# STM32H7B0x register map
File version: 1.0
CPU: CM7 r0p1, little endian, MPU, FPU, 4 interrupt priority bits
Registers are 32-bit, read-write, reset 0x0 unless marked. A register's access mark holds for its fields unless they carry their own. Offsets are from the block's base; [hi:lo] are bit positions; {n}, {i} and the like mark numbered series.

## NVIC — Nested Vectored Interrupt Controller
Base 0xE000E100
{0x0+4i} ISER{i} (i=0..2) — Interrupt Set-Enable Register
  [31:0] SETENA
{0x80+4i} ICER{i} (i=0..2) — Interrupt Clear-Enable Register
  [31:0] CLRENA
{0x100+4i} ISPR{i} (i=0..2) — Interrupt Set-Pending Register
  [31:0] SETPEND
{0x180+4i} ICPR{i} (i=0..2) — Interrupt Clear-Pending Register
  [31:0] CLRPEND
{0x200+4i} IABR{i} ro (i=0..2) — Interrupt Active Bit Register
  [31:0] ACTIVE
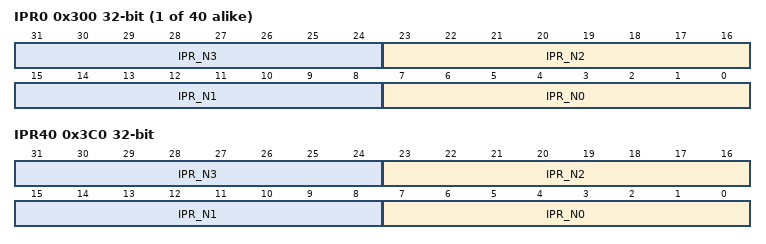
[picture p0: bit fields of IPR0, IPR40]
{0x300+4i} IPR{i} (i=0..39) — Interrupt Priority Register
  [8n+7:8n] IPR_N{n} (n=0..3)
0x3A0 ISER3 — Interrupt Set-Enable Register
  [31:0] SETENA
0x3A4 ISER4 — Interrupt Set-Enable Register
  [31:0] SETENA
0x3A8 ICER3 — Interrupt Clear-Enable Register
  [31:0] CLRENA
0x3AC ICER4 — Interrupt Clear-Enable Register
  [31:0] CLRENA
0x3B0 ISPR3 — Interrupt Set-Pending Register
  [31:0] SETPEND
0x3B4 ISPR4 — Interrupt Set-Pending Register
  [31:0] SETPEND
0x3B8 IABR3 ro — Interrupt Active Bit Register
  [31:0] ACTIVE
0x3BC IABR4 ro — Interrupt Active Bit Register
  [31:0] ACTIVE
0x3C0 IPR40 — Interrupt Priority Register
  [8n+7:8n] IPR_N{n} (n=0..3)

## DBGMCU — Microcontroller Debug Unit
Base 0x5C001000
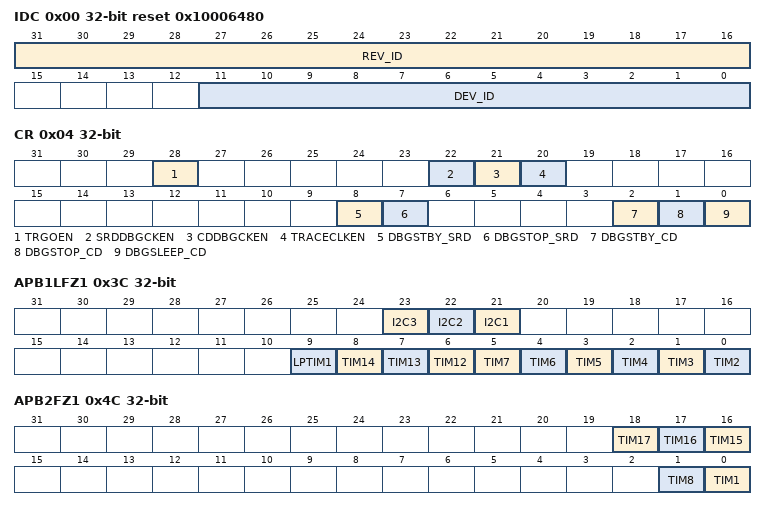
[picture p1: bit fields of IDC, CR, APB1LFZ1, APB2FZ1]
0x00 IDC ro reset 0x10006480 — DBGMCU Identity Code Register
  [31:16] REV_ID — Revision
  [11:0] DEV_ID — Device ID
0x04 CR — DBGMCU Configuration Register
  [28] TRGOEN — External trigger output enable
  [22] SRDDBGCKEN — SmartRun domain debug clock enable
  [21] CDDBGCKEN — CPU domain debug clock enable
  [20] TRACECLKEN — Trace port clock enable
  [8] DBGSTBY_SRD — debug in SmartRun domain Standby mode
  [7] DBGSTOP_SRD — debug in SmartRun domain Stop mode
  [2] DBGSTBY_CD — Allow D1 domain debug in Standby mode
  [1] DBGSTOP_CD — Allow D1 domain debug in Stop mode
  [0] DBGSLEEP_CD — Allow D1 domain debug in Sleep mode
0x34 APB3FZ1 — DBGMCU APB3 peripheral freeze register
  [6] WWDG — WWDG stop in debug
0x3C APB1LFZ1 — DBGMCU APB1L peripheral freeze register
  [23] I2C3 — I2C3 SMBUS timeout stop in debug
  [22] I2C2 — I2C2 SMBUS timeout stop in debug
  [21] I2C1 — I2C1 SMBUS timeout stop in debug
  [9] LPTIM1 — LPTIM1 stop in debug
  [8] TIM14 — TIM14 stop in debug
  [7] TIM13 — TIM13 stop in debug
  [6] TIM12 — TIM12 stop in debug
  [n-2] TIM{n} (n=2..7) — TIM{n} stop in debug
0x4C APB2FZ1 — DBGMCU APB2 peripheral freeze register
  [18] TIM17 — TIM17 stop in debug
  [17] TIM16 — TIM16 stop in debug
  [16] TIM15 — TIM15 stop in debug
  [1] TIM8 — TIM8 stop in debug
  [0] TIM1 — TIM1 stop in debug
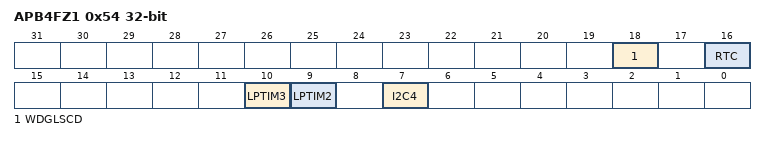
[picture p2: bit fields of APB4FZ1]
0x54 APB4FZ1 — DBGMCU APB4 peripheral freeze register
  [18] WDGLSCD — LS watchdog for CPU domain stop in debug
  [16] RTC — RTC stop in debug
  [10] LPTIM3 — LPTIM3 stop in debug
  [9] LPTIM2 — LPTIM2 stop in debug
  [7] I2C4 — I2C4 SMBUS timeout stop in debug

## SYSCFG — System configuration controller
Base 0x58000400
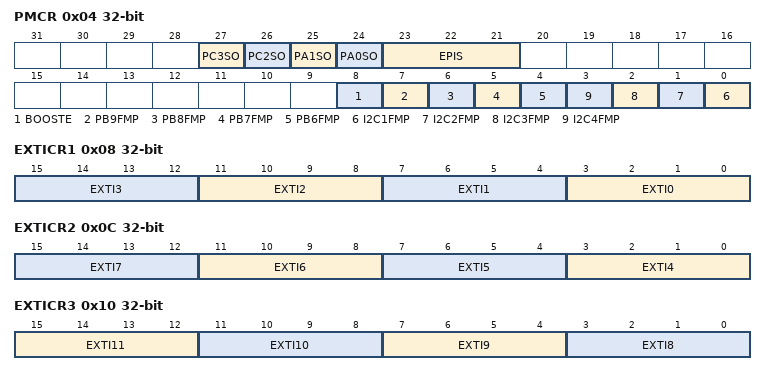
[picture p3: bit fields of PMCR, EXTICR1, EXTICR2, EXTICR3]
0x04 PMCR — peripheral mode configuration register
  [27] PC3SO — PC3 Switch Open
  [26] PC2SO — PC2 Switch Open
  [25] PA1SO — PA1 Switch Open
  [24] PA0SO — PA0 Switch Open
  [23:21] EPIS — Ethernet PHY Interface Selection
  [8] BOOSTE — Booster Enable
  [7] PB9FMP — PB(9) Fm+
  [6] PB8FMP — PB(8) Fast Mode Plus
  [5] PB7FMP — PB(7) Fast Mode Plus
  [4] PB6FMP — PB(6) Fm+
  [n-1] I2C{n}FMP (n=1..4) — I2C{n} Fm+
0x08 EXTICR1 — external interrupt configuration register 1
  [4n+3:4n] EXTI{n} (n=0..3) — EXTI x configuration (x = 0 to 3)
0x0C EXTICR2 — external interrupt configuration register 2
  [4n-13:4n-16] EXTI{n} (n=4..7) — EXTI x configuration (x = 4 to 7)
0x10 EXTICR3 — external interrupt configuration register 3
  [15:12] EXTI11 — EXTI x configuration (x = 8 to 11)
  [11:8] EXTI10
  [7:4] EXTI9 — EXTI x configuration (x = 8 to 11)
  [3:0] EXTI8 — EXTI x configuration (x = 8 to 11)
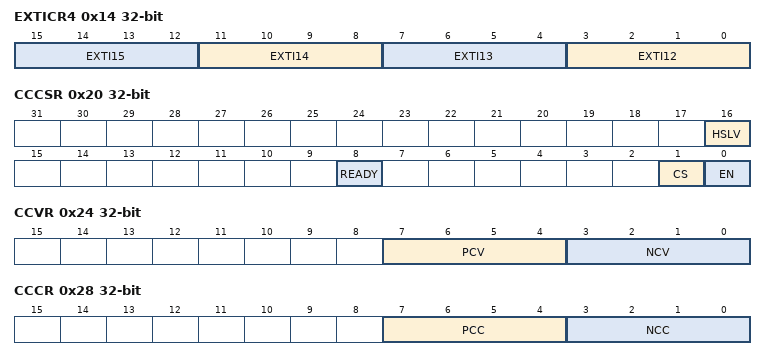
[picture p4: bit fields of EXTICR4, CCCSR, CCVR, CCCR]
0x14 EXTICR4 — external interrupt configuration register 4
  [4n-45:4n-48] EXTI{n} (n=12..15) — EXTI x configuration (x = 12 to 15)
0x20 CCCSR — compensation cell control/status register
  [16] HSLV — High-speed at low-voltage
  [8] READY — Compensation cell ready flag
  [1] CS — Code selection
  [0] EN — enable
0x24 CCVR ro — SYSCFG compensation cell value register
  [7:4] PCV — PMOS compensation value
  [3:0] NCV — NMOS compensation value
0x28 CCCR — SYSCFG compensation cell code register
  [7:4] PCC — PMOS compensation code
  [3:0] NCC — NMOS compensation code
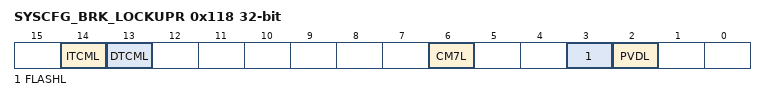
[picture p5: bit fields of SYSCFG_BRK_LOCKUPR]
0x118 SYSCFG_BRK_LOCKUPR — SYSCFG timer break lockup register
  [14] ITCML — ITCM double ECC error signal lock
  [13] DTCML — D1TCM or D0TCM double ECC error signal lock
  [6] CM7L — CortexÃ‚Â®-M7 LOCKUP (HardFault) output enable bit
  [3] FLASHL — Flash double ECC error lock bit
  [2] PVDL — PVD lock enable bit.
